# nrf54l15_application register map
Vendor: Nordic Semiconductor; Series: nrf54l; File version: 1
CPU: CM33 r0p4, little endian, MPU, FPU, 3 interrupt priority bits, 270 interrupts, 4 SAU regions
Registers are 32-bit, read-write, reset 0x0 unless marked. A register's access mark holds for its fields unless they carry their own. Offsets are from the block's base; [hi:lo] are bit positions; lines under a group give offsets from that group; {n}, {i} and the like mark numbered series; 'fields as' and 'values as' point back to an identical list.

## GLOBAL_SAADC_NS — Analog to Digital Converter 0
Base 0x400D5000
Same registers: GLOBAL_SAADC_S 0x500D5000
0x00 TASKS_START wo — Start the ADC and prepare the result buffer in RAM
  [0] TASKS_START
    1=Trigger task
0x04 TASKS_SAMPLE wo — Take one ADC sample, if scan is enabled all channels are sampled. This task requires that SAADC has started, i.e. EVENTS_STARTED was set and EVENTS_STOPPED was not.
  [0] TASKS_SAMPLE
    1=Trigger task
0x08 TASKS_STOP wo — Stop the ADC and terminate any on-going conversion
  [0] TASKS_STOP
    1=Trigger task
0x0C TASKS_CALIBRATEOFFSET wo — Starts offset auto-calibration Noise shaping should be disabled
  [0] TASKS_CALIBRATEOFFSET
    1=Trigger task
0x10 TASKS_CALIBRATELINEARITY wo — Starts linearity auto-calibration. TESTCTRL field LIN_CAL_ENABLE must be low. Noise shaping must be disabled.
  [0] TASKS_CALIBRATELINEARITY
    1=Trigger task
0x14 TASKS_CALIBRATEGAIN wo — Starts gain auto-calibration
  [0] TASKS_CALIBRATEGAIN
    1=Trigger task
0x18 TASKS_STOPDMA wo — Stops DMA transfer sub module
  [0] TASKS_STOPDMA
    1=Trigger task
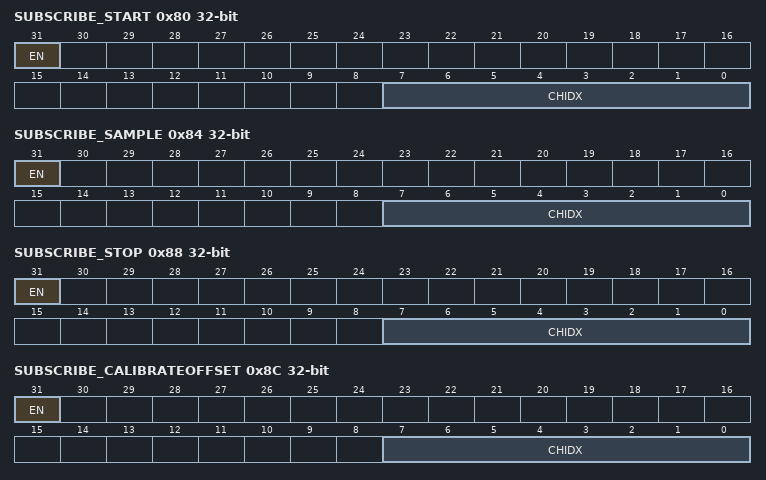
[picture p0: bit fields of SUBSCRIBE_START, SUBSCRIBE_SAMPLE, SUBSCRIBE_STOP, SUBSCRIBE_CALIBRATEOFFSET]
0x80 SUBSCRIBE_START — Subscribe configuration for task START
  [31] EN
    0=Disabled (Disable subscription); 1=Enabled (Enable subscription)
  [7:0] CHIDX — DPPI channel that task START will subscribe to
0x84 SUBSCRIBE_SAMPLE — Subscribe configuration for task SAMPLE
  [31] EN
    values as SUBSCRIBE_START.EN
  [7:0] CHIDX — DPPI channel that task SAMPLE will subscribe to
0x88 SUBSCRIBE_STOP — Subscribe configuration for task STOP
  [31] EN
    values as SUBSCRIBE_START.EN
  [7:0] CHIDX — DPPI channel that task STOP will subscribe to
0x8C SUBSCRIBE_CALIBRATEOFFSET — Subscribe configuration for task CALIBRATEOFFSET
  [31] EN
    values as SUBSCRIBE_START.EN
  [7:0] CHIDX — DPPI channel that task CALIBRATEOFFSET will subscribe to
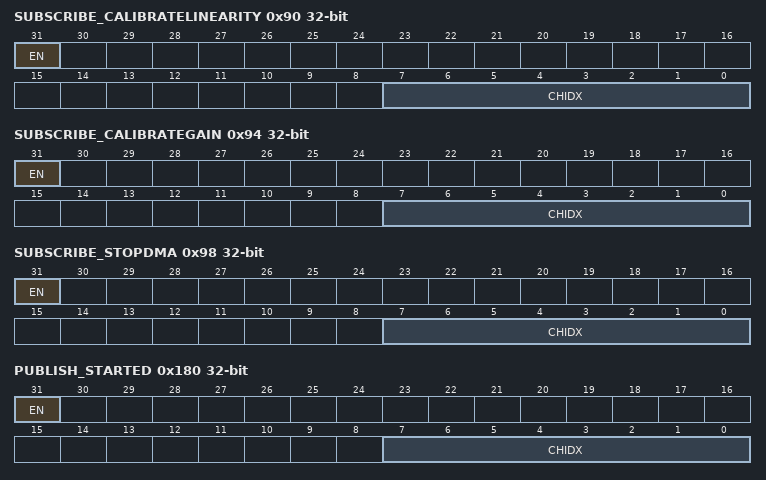
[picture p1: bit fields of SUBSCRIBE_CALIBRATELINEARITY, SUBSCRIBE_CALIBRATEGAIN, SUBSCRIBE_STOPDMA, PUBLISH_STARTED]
0x90 SUBSCRIBE_CALIBRATELINEARITY — Subscribe configuration for task CALIBRATELINEARITY
  [31] EN
    values as SUBSCRIBE_START.EN
  [7:0] CHIDX — DPPI channel that task CALIBRATELINEARITY will subscribe to
0x94 SUBSCRIBE_CALIBRATEGAIN — Subscribe configuration for task CALIBRATEGAIN
  [31] EN
    values as SUBSCRIBE_START.EN
  [7:0] CHIDX — DPPI channel that task CALIBRATEGAIN will subscribe to
0x98 SUBSCRIBE_STOPDMA — Subscribe configuration for task STOPDMA
  [31] EN
    values as SUBSCRIBE_START.EN
  [7:0] CHIDX — DPPI channel that task STOPDMA will subscribe to
0x100 EVENTS_STARTED — The ADC DMA has started
  [0] EVENTS_STARTED
    0=NotGenerated (Event not generated); 1=Generated (Event generated)
0x104 EVENTS_END — The ADC has filled up the Result buffer
  [0] EVENTS_END
    values as EVENTS_STARTED.EVENTS_STARTED
0x108 EVENTS_DONE — A conversion task has been completed. Depending on the mode, multiple conversions might be needed for a result to be transferred to RAM.
  [0] EVENTS_DONE
    values as EVENTS_STARTED.EVENTS_STARTED
0x10C EVENTS_RESULTDONE — A result is ready to get transferred to RAM. Result is available in REGRESULT register
  [0] EVENTS_RESULTDONE
    values as EVENTS_STARTED.EVENTS_STARTED
0x110 EVENTS_CALIBRATEDONE — Calibration is complete
  [0] EVENTS_CALIBRATEDONE
    values as EVENTS_STARTED.EVENTS_STARTED
0x114 EVENTS_STOPPED — The ADC DMA has stopped
  [0] EVENTS_STOPPED
    values as EVENTS_STARTED.EVENTS_STARTED
{0x118+8i} EVENTS_CH[{i}] (i=0..7) group — Peripheral events.
  0x00 LIMITH — Description cluster: Last results is above CH[n].LIMIT.HIGH
    [0] LIMITH — Last results is above CH[n].LIMIT.HIGH
      values as EVENTS_STARTED.EVENTS_STARTED
  0x04 LIMITL — Description cluster: Last results is below CH[n].LIMIT.LOW
    [0] LIMITL — Last results is below CH[n].LIMIT.LOW
      values as EVENTS_STARTED.EVENTS_STARTED
0x158 EVENTS_AHBERROR — EasyDMA encountered AHB error.
  [0] EVENTS_AHBERROR
    values as EVENTS_STARTED.EVENTS_STARTED
0x180 PUBLISH_STARTED — Publish configuration for event STARTED
  [31] EN
    0=Disabled (Disable publishing); 1=Enabled (Enable publishing)
  [7:0] CHIDX — DPPI channel that event STARTED will publish to
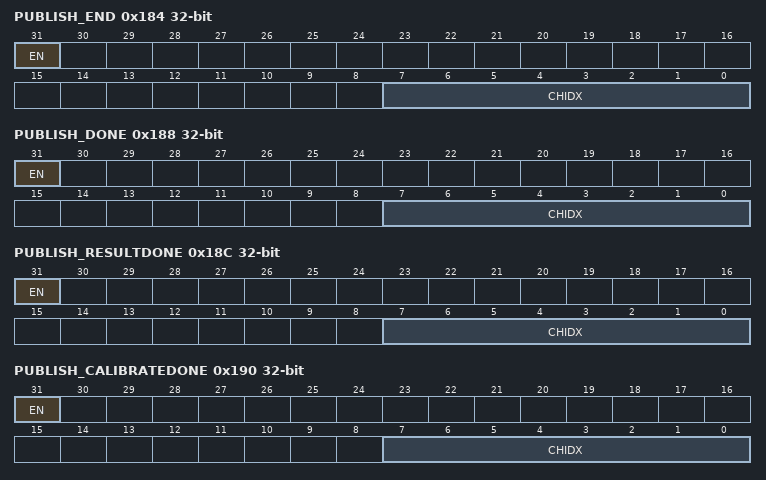
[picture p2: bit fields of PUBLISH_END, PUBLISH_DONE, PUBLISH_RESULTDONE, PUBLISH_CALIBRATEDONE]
0x184 PUBLISH_END — Publish configuration for event END
  [31] EN
    values as PUBLISH_STARTED.EN
  [7:0] CHIDX — DPPI channel that event END will publish to
0x188 PUBLISH_DONE — Publish configuration for event DONE
  [31] EN
    values as PUBLISH_STARTED.EN
  [7:0] CHIDX — DPPI channel that event DONE will publish to
0x18C PUBLISH_RESULTDONE — Publish configuration for event RESULTDONE
  [31] EN
    values as PUBLISH_STARTED.EN
  [7:0] CHIDX — DPPI channel that event RESULTDONE will publish to
0x190 PUBLISH_CALIBRATEDONE — Publish configuration for event CALIBRATEDONE
  [31] EN
    values as PUBLISH_STARTED.EN
  [7:0] CHIDX — DPPI channel that event CALIBRATEDONE will publish to
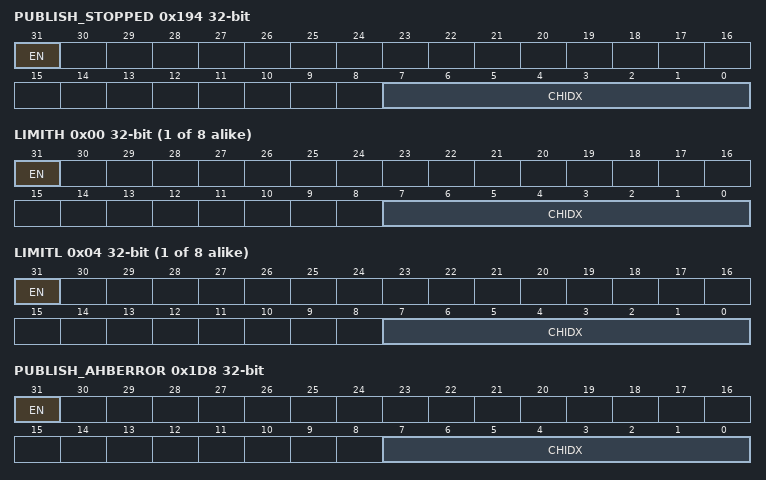
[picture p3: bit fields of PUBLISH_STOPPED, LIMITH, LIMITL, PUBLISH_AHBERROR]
0x194 PUBLISH_STOPPED — Publish configuration for event STOPPED
  [31] EN
    values as PUBLISH_STARTED.EN
  [7:0] CHIDX — DPPI channel that event STOPPED will publish to
{0x198+8i} PUBLISH_CH[{i}] (i=0..7) group — Publish configuration for events
  0x00 LIMITH — Description cluster: Publish configuration for event CH[n].LIMITH
    [31] EN
      values as PUBLISH_STARTED.EN
    [7:0] CHIDX — DPPI channel that event CH[n].LIMITH will publish to
  0x04 LIMITL — Description cluster: Publish configuration for event CH[n].LIMITL
    [31] EN
      values as PUBLISH_STARTED.EN
    [7:0] CHIDX — DPPI channel that event CH[n].LIMITL will publish to
0x1D8 PUBLISH_AHBERROR — Publish configuration for event AHBERROR
  [31] EN
    values as PUBLISH_STARTED.EN
  [7:0] CHIDX — DPPI channel that event AHBERROR will publish to
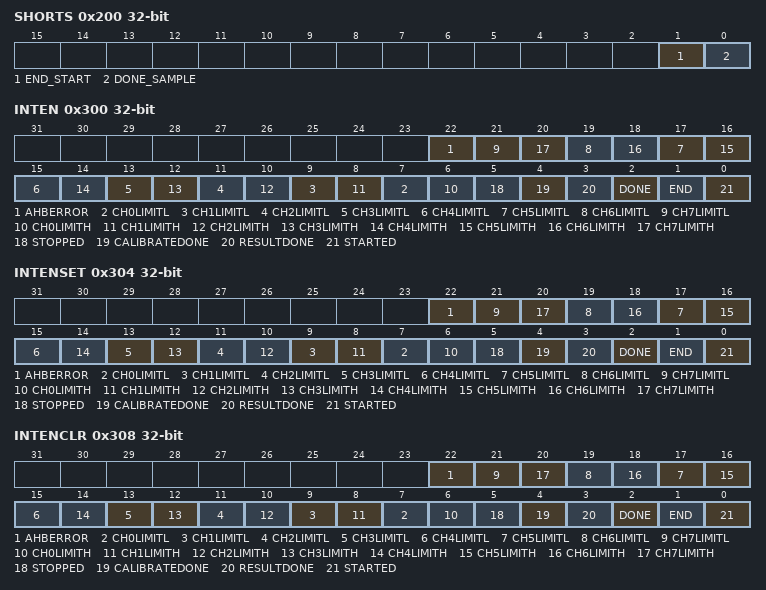
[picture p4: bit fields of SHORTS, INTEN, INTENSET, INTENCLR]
0x200 SHORTS — Shortcuts between local events and tasks
  [1] END_START — Shortcut between event END and task START
    0=Disabled (Disable shortcut); 1=Enabled (Enable shortcut)
  [0] DONE_SAMPLE — Shortcut between event DONE and task SAMPLE
    0=Disabled (Disable shortcut); 1=Enabled (Enable shortcut)
0x300 INTEN — Enable or disable interrupt
  [all] fields
    0=Disabled; 1=Enabled
  [22] AHBERROR — Enable or disable interrupt for event AHBERROR
  [2n+7] CH{n}LIMITL (n=0..7) — Enable or disable interrupt for event CH{n}LIMITL
  [2n+6] CH{n}LIMITH (n=0..7) — Enable or disable interrupt for event CH{n}LIMITH
  [5] STOPPED — Enable or disable interrupt for event STOPPED
  [4] CALIBRATEDONE — Enable or disable interrupt for event CALIBRATEDONE
  [3] RESULTDONE — Enable or disable interrupt for event RESULTDONE
  [2] DONE — Enable or disable interrupt for event DONE
  [1] END — Enable or disable interrupt for event END
  [0] STARTED — Enable or disable interrupt for event STARTED
0x304 INTENSET — Enable interrupt
  [all] fields
    on read: 0=Disabled (Read: Disabled); 1=Enabled (Read: Enabled) | on write: 1=Set (Enable)
  [22] AHBERROR — Write '1' to enable interrupt for event AHBERROR
  [2n+7] CH{n}LIMITL (n=0..7) — Write '1' to enable interrupt for event CH{n}LIMITL
  [2n+6] CH{n}LIMITH (n=0..7) — Write '1' to enable interrupt for event CH{n}LIMITH
  [5] STOPPED — Write '1' to enable interrupt for event STOPPED
  [4] CALIBRATEDONE — Write '1' to enable interrupt for event CALIBRATEDONE
  [3] RESULTDONE — Write '1' to enable interrupt for event RESULTDONE
  [2] DONE — Write '1' to enable interrupt for event DONE
  [1] END — Write '1' to enable interrupt for event END
  [0] STARTED — Write '1' to enable interrupt for event STARTED
0x308 INTENCLR — Disable interrupt
  [all] fields
    on read: 0=Disabled (Read: Disabled); 1=Enabled (Read: Enabled) | on write: 1=Clear (Disable)
  [22] AHBERROR — Write '1' to disable interrupt for event AHBERROR
  [2n+7] CH{n}LIMITL (n=0..7) — Write '1' to disable interrupt for event CH{n}LIMITL
  [2n+6] CH{n}LIMITH (n=0..7) — Write '1' to disable interrupt for event CH{n}LIMITH
  [5] STOPPED — Write '1' to disable interrupt for event STOPPED
  [4] CALIBRATEDONE — Write '1' to disable interrupt for event CALIBRATEDONE
  [3] RESULTDONE — Write '1' to disable interrupt for event RESULTDONE
  [2] DONE — Write '1' to disable interrupt for event DONE
  [1] END — Write '1' to disable interrupt for event END
  [0] STARTED — Write '1' to disable interrupt for event STARTED
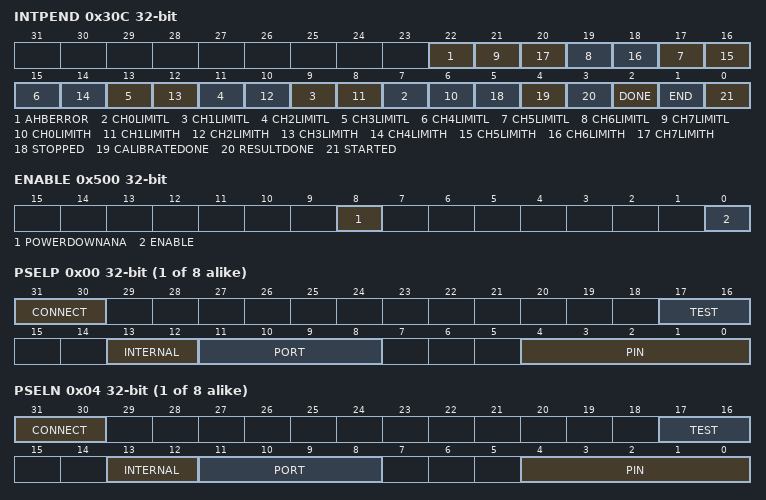
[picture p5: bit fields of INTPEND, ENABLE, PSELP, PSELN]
0x30C INTPEND ro — Pending interrupts
  [all] fields
    on read: 0=NotPending (Read: Not pending); 1=Pending (Read: Pending)
  [22] AHBERROR — Read pending status of interrupt for event AHBERROR
  [2n+7] CH{n}LIMITL (n=0..7) — Read pending status of interrupt for event CH{n}LIMITL
  [2n+6] CH{n}LIMITH (n=0..7) — Read pending status of interrupt for event CH{n}LIMITH
  [5] STOPPED — Read pending status of interrupt for event STOPPED
  [4] CALIBRATEDONE — Read pending status of interrupt for event CALIBRATEDONE
  [3] RESULTDONE — Read pending status of interrupt for event RESULTDONE
  [2] DONE — Read pending status of interrupt for event DONE
  [1] END — Read pending status of interrupt for event END
  [0] STARTED — Read pending status of interrupt for event STARTED
0x400 STATUS ro
  [0] STATUS
    0=Ready (ADC is ready. No on-going conversion.); 1=Busy (ADC is busy. Conversion is in progress.)
0x404 PCRMSTATUS ro
  [0] ACK — PCRM Ack Status for the PCRM clean power request
    0=NoAck (Ack not received.); 1=Ack (Ack received.)
0x408 STATUSANA ro — Status bit for analog macro
  [0] POWERED
    1=Powered (Analog macro is fully powered on); 0=Unpowered (Analog macro is not fully powered on)
0x440 TRIM group — Unspecified
  {0x0+4j} LINCALCOEFF[{j}] (j=0..5) — Description collection: Linearity calibration coefficient
    [15:0] VAL — value
0x500 ENABLE — Enable or disable ADC
  [8] POWERDOWNANA — Power down analog between samples.
    0=KeepOn (Keep analog on between samples); 1=PowerDown (Turn off analog between samples)
  [0] ENABLE — Enable or disable ADC
    0=Disabled (Disable ADC); 1=Enabled (Enable ADC)
{0x510+0x10*i} CH[{i}] (i=0..7) group — Unspecified
  0x00 PSELP — Description cluster: Input positive pin selection for CH[n]
    [31:30] CONNECT — Connection
      0=NC (Not connected); 1=AnalogInput (Select analog input); 2=Internal (Selects internal inputs.); 3=Test (Selects test inputs.)
    [17:16] TEST — Test input selection for Analog positive input when CH[n].PSELP.CONNECT = Test
      0=ATB2; 1=ATB1; 2=AVSS; 3=SELREF (Selected reference, voltage determined by PADC_REFSEL)
    [13:12] INTERNAL — Internal input selection for analog positive input when CH[n].PSELP.CONNECT = Internal
      0=Avdd (Connected to the internal 0.9V analog supply rail); 1=Dvdd (Connected to the internal 0.9V digital supply rail); 2=Vdd (Connected to VDD); 3=Reserved for future use
    [11:8] PORT — GPIO port selection
    [4:0] PIN — GPIO pin selection.
  0x04 PSELN — Description cluster: Input negative pin selection for CH[n]
    [31:30] CONNECT — Connection
      values as CH[0].PSELP.CONNECT
    [17:16] TEST — Test input selection for Analog negative input when CH[n].PSELN.CONNECT = Test
      0=ATB0; 1=ATB1; 2=AVSS; 3=SELREF (Selected reference, voltage determined by PADC_REFSEL)
    [13:12] INTERNAL — Internal input selection for Analog negative input when CH[n].PSELN.CONNECT = Internal
      0=Connected to VDD_ANA_0V9; 1=Connected to VDD_DIG_0V9; 2=Connected to VDD_AO_3V0; 3=Reserved for future use
    [11:8] PORT — GPIO Port selection
    [4:0] PIN — GPIO pin selection.
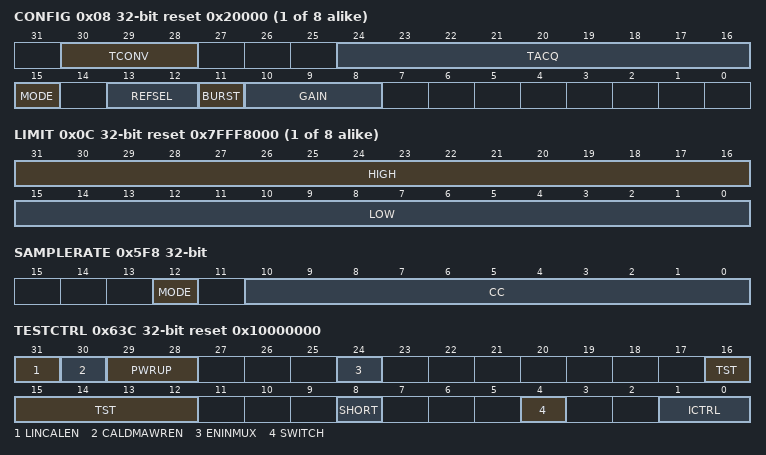
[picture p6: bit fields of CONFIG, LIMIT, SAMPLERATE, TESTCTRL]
  0x08 CONFIG reset 0x20000 — Description cluster: Input configuration for CH[n]
    [30:28] TCONV — Conversion time. Resulting conversion time is ((TCONV+1) x 250 ns)
    [24:16] TACQ — Acquisition time, the time the ADC uses to sample the input voltage. Resulting acquistion time is ((TACQ+1) x 125 ns)
    [15] MODE — Enable differential mode
      0=SE (Single ended, PSELN will be ignored, negative input to ADC shorted to GND); 1=Differential
    [13:12] REFSEL — Reference control
      0=Internal reference (0.9 V); 1=External reference given at PADC_EXT_REF_1V2
    [11] BURST — Enable burst mode
      0=Disabled (Burst mode is disabled (normal operation)); 1=Enabled (Burst mode is enabled. SAADC takes 2^OVERSAMPLE number of samples as fast as it can, and sends the average to Data RAM.)
    [10:8] GAIN — Gain control
      0=2; 1=1; {v}=Gain2_{v+1} (2/{v+1}) (v=2..7)
  0x0C LIMIT reset 0x7FFF8000 — Description cluster: High/low limits for event monitoring a channel
    [31:16] HIGH — High level limit
    [15:0] LOW — Low level limit
0x5EC REGRESULT ro — Last conversion result
  [31:0] REGRESULT — Result of the previous ADC conversion, as written to RAM
0x5F0 RESOLUTION reset 0x1 — Resolution configuration
  [2:0] VAL — Set the resolution
    0=8bit; 1=10bit; 2=12bit; 3=14bit; 4=16bit
0x5F4 OVERSAMPLE — Oversampling configuration. OVERSAMPLE should not be combined with SCAN unless burst is enabled. The RESOLUTION is applied before averaging, thus for high OVERSAMPLE a higher RESOLUTION should be used.
  [3:0] OVERSAMPLE — Oversample control
    0=Bypass oversampling; 1=Over2x (Oversample 2x); 2=Over4x (Oversample 4x); 3=Over8x (Oversample 8x); 4=Over16x (Oversample 16x); 5=Over32x (Oversample 32x); 6=Over64x (Oversample 64x); 7=Over128x (Oversample 128x); 8=Over256x (Oversample 256x); 9=Over512x (Oversample 512x); 10=Over1024x (Oversample 1024x); 11=Over2048x (Oversample 2048x); 12=Over4096x (Oversample 4096x)
0x5F8 SAMPLERATE — Configures the sampling rate for either task-triggered or continuous operation using a local timer
  [12] MODE — Select mode for sample rate control
    0=Task (Rate is controlled from SAMPLE task); 1=Timers (Rate is controlled from local timer (use CC to control the rate))
  [10:0] CC — Capture and compare value. Sample rate is 16 MHz/CC
0x5FC PCRMREQ — PCRM request for clean power
  [0] REQ — Request
    0=Disabled (Request disabled.); 1=Enabled (Request enabled.)
0x628 RESULT group — RESULT EasyDMA channel
  0x00 DMAENABLE — This register has no other function than defining the value on the dmaChannelPeripheralEnable output. (which is not connected)
    [0] ENABLE — Enable DMA
  0x04 PTR — Data pointer
  0x08 MAXCNT — Maximum number of buffer bytes to transfer. Note that one sample is two bytes.
    [14:0] MAXCNT
  0x0C AMOUNT ro — Number of buffer bytes transferred since last START, updated after the END or STOPPED events
    [14:0] AMOUNT — Number of buffer bytes transferred since last START, updated after the END or STOPPED events.
  0x10 CURRENTAMOUNT ro — Number of buffer bytes transferred since last START, continuously updated
    [14:0] AMOUNT — Number of buffer bytes transferred since last START, continuously updated.
0x63C TESTCTRL reset 0x10000000 — Control signals used during test of ADC
  [31] LINCALEN — Enables the use of linear calibration values TRIM.LINCALCOEFF[n]
    0=Disabled (Use of linear calibration is disabled); 1=Enabled (Use of linear calibration is enabled)
  [30] CALDMAWREN — Enable writing calibration values to DMA
    0=Disabled (Writing values is disabled); 1=Enabled (Writing values is enabled)
  [29:28] PWRUP — Power-up time
    0=6us; 1=10us; 2=15us; 3=20us
  [24] ENINMUX — Will enable the input mux in the ADC. See design description for coding.
  [16:12] TST — Test bus for ADC core. See design description for coding
  [8] SHORT — Short input. Used to measure offset of ADC. See design description for coding
  [4] SWITCH — Swap positive and negative input. See design description for coding
  [1:0] ICTRL — Multiply the current level of the internal bias current IBPSR_10U
    2=I20uA (20 uA); 3=I15uA (15 uA); 0=I10uA (10 uA (default)); 1=I5uA (5 uA)
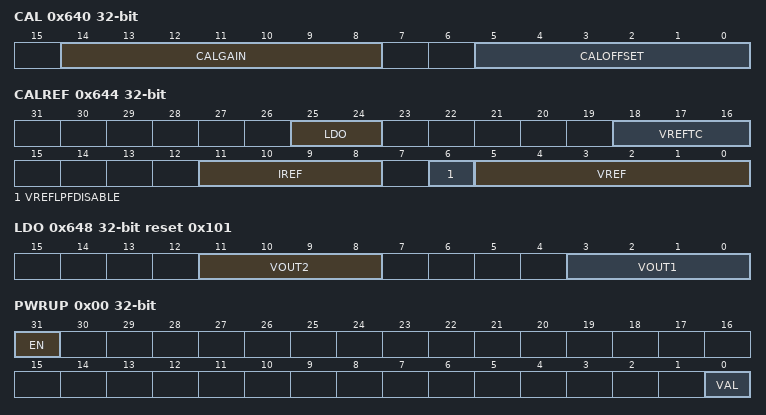
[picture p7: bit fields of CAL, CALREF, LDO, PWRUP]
0x640 CAL — Calibration control for offset and gain error
  [14:8] CALGAIN — Offset binary coding
    0=Default gain, for +1/2 input (assume full-scale = +-1) the output will be 1024; 63=High gain setting; 64=Low (Low gain setting)
  [5:0] CALOFFSET — Calibration control for offset error. Sign-magnitude coding
    0=Default setting; 31=MaxPos (Maximum positive offset); 32=MaxNeg (maximum negative offset)
0x644 CALREF — Calibration control for reference voltage
  [25:24] LDO — Calibration code for LDO VREF. See design description for coding
  [18:16] VREFTC — Calibration code for reference temperature coefficient. See design description for coding
  [11:8] IREF — Calibration control for reference current. IREF is 2s complement, 4.45 percent step size
    7=Max (Maximum current (+31.3 percent ish)); 0=Default current (10uA); 8=Min (Minimum current (-35.6 percent ish))
  [6] VREFLPFDISABLE — Disable the internal reference low pass filter
  [5:0] VREF — Offset binary coding
    0=Default vref, in typical corner VREF=0.9V; 63=High (Low output code (high reference voltage)); 0=Low (High output code (low reference voltage))
0x648 LDO reset 0x101 — Internal LDO output voltage control
  [11:8] VOUT2 — Secontary LDO output voltage control. See design description for coding
  [3:0] VOUT1 — Primary LDO output voltage control. See design description for coding
0x654 NOISESHAPE — SAADC provides two operational noise shaping modes (one that prioritizes higher bandwith, while the other prioritizes higher accuracy) that allow trade-offs between ADC resolution, power consumption, and signal bandwidth.
  [1:0] NOISESHAPE — Noise shaping configuration
    0=Disable noiseshaping. Configurable oversampling.; 1=NS1 (Noiseshaping and decimating. Larger passband. Decimation ratio 8, 125 kS/s, with resulting bandwidth around 45 kHz. Takes precedence over the OVERSAMPLING register.); 2=NS2 (Noiseshaping and decimating. Smaller passband. Decimation ratio 32, 31.25 kS/s, with resulting bandwidth around 7 kHz. Takes precedence over the OVERSAMPLING register.); 3=Stage1 (Moonlight/Lilium: Result from common 1st stage filter. For debugging only. Configurable oversampling, but this mode without oversampling is not meaningful (noise shaping one sample)); 1=Audio (Deprecated enumerator - Use enumerator NS1 for future compatibility.); 2=Accuracy (Deprecated enumerator - Use enumerator NS2 for future compatibility.)
0x658 EASYDMAMODE reset 0x1 — Configure EasyDMA mode.
  [0] LPOP — Enable low-power operation, or use low-latency
    0=Low-latency operation; 1=Low-power operation
0x660 TERMINATEONAHBERROR — Enable EasyDMA termination on AHB error
  [0] ENABLE — Enable termination on AHB error
    0=Disabled (Termination on AHB error disabled); 1=Enabled (Termination on AHB error enabled)
0x664 AHBERRORADDRESS ro — Address of the last AHB error transaction
  [31:0] ADDRESS
0x700 OVERRIDE group — Unspecified
  0x00 PWRUP — Override the PWRUP signal to the analog module
    [31] EN — Enable the override
      0=Disabled (Override is disabled); 1=Enabled (Override is enabled)
    [0] VAL — Override value for the signal
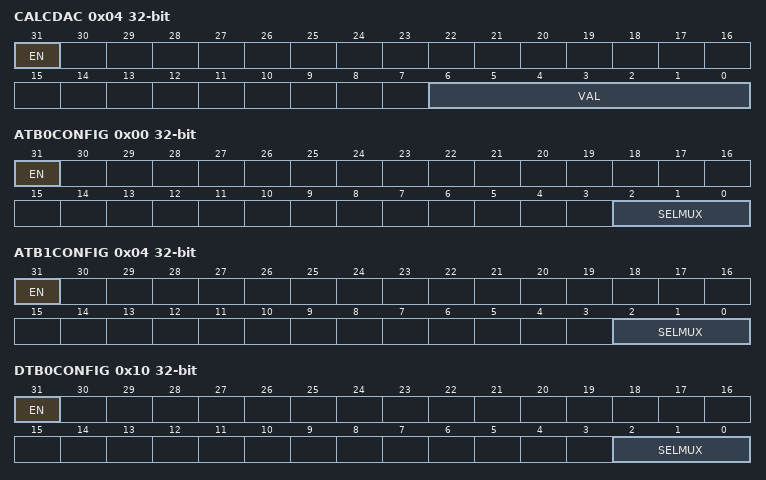
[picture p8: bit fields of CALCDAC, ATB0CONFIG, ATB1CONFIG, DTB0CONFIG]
  0x04 CALCDAC — Override the CAL_CDAC signal to the analog module
    [31] EN — Enable the override
      values as OVERRIDE.PWRUP.EN
    [6:0] VAL — Override value for the signal
0x800 DFT group — Unspecified
  0x00 ATB0CONFIG — Analog Test Bus 0 (ATB0) configuration
    [31] EN — Enable the analog test bus
      0=Disabled (Analog test bus is disabled); 1=Enabled (Analog test bus is enabled)
    [2:0] SELMUX — Select multiplexer for ATB0
      0=InMux (ATB0 connected to PADC_INMUX, available on PADC_IN); 1=Vref (ATB0 connected to VREF); 2=VrefBuff (ATB0 connected to VREF_BUFF); 3=VrefIbpsr10U (ATB0 connected to ATB_PADC_VREF_IBPSR_10U for current measurement); 4=VrefIbps3U (ATB0 connected to ATB_PADC_VREF_IBPS_3U); 5=VrefLpfDisabled (ATB0 connected to VREF, internal reference with LPF bypassed.); 6=Spare1 (Spare pin); 7=Spare2 (Spare pin)
  0x04 ATB1CONFIG — Analog Test Bus 1 (ATB1) configuration
    [31] EN — Enable the analog test bus
      values as DFT.ATB0CONFIG.EN
    [2:0] SELMUX — Select multiplexer for ATB1
      0=Inmux (ATB1 connected to PADC_INMUX, available on both PADC_IP and PADC_IN); 1=VrefViaAtbuf (ATB1 connected to VREF via ATBBUF); 2=VrefBuffViaAtbuf (ATB1 connected to VREF_BUFF via ATBUF); 3=Ldo (ATB1 connected to PADC_LDO to measure 1.5V via ATBUF); 4=Spare0 (Unspecified); 5=VrefLdo (ATB1 connected to VREF_LDO to measure 1.5V via ATBUF); 6=Spare1 (Spare pin); 7=Spare2 (Spare pin)
  0x08 ATB2CONFIG — Analog Test Bus 2 (ATB2) configuration
    [31] EN — Enable the analog test bus
      0=Disabled (Analog test bus is disabled); 1=Enabled (Analog test bus is enabled and connected to PADC_INMUX available on PADC_IP)
  0x10 DTB0CONFIG — Digital Test Bus 0 (DTB0) configuration
    [31] EN — Enable the digital test bus
      0=Disabled (Digital test bus is disabled); 1=Enabled (Digital test bus is enabled)
    [2:0] SELMUX — Select multiplexer for DTB0
      0=READY (READY_PADC_AO_0V8); 1=READYVREF (READY_PADC_VREF_AO_0V8); 2=SETTLED (SETTLED_VDD_INT_AO_0V8); 3=INTCONVERT (INT_CONVERT_0V8); 4=INTDONE (INT_DONE_0V8); 5=INTAMPLFIY (INT_AMPLFIY_0V8); 6=Spare0 (Spare pin); 7=Spare1 (Spare pin)
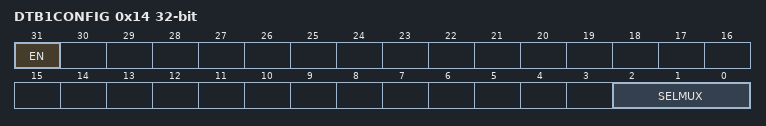
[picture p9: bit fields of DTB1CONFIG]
  0x14 DTB1CONFIG — Digital Test Bus 1 (DTB1) configuration
    [31] EN — Enable the digital test bus
      values as DFT.DTB0CONFIG.EN
    [2:0] SELMUX — Select multiplexer for DTB1
      0=INTIDLE (INT_IDLE_0V8); 1=INTSAMPLE (INT_SAMPLE_0V8); 2=INTAMPLFIY (INT_AMPLFIY_0V8); 3=INTCONVERT (INT_CONVERT_0V8); 4=INTDONE (INT_DONE_0V8); 5=ENNSERRFEEDBACK (EN_NS_ERR_FEEDBACK_0V8); 6=Spare0 (Spare pin); 7=Spare1 (Spare pin)

## Notices in the file
Copyright (c) 2010 - 2025, Nordic Semiconductor ASA
All rights reserved.
Redistribution and use in source and binary forms, with or without modification,
are permitted provided that the following conditions are met:
1. Redistributions of source code must retain the above copyright notice, this
list of conditions and the following disclaimer.
2. Redistributions in binary form, except as embedded into a Nordic
Semiconductor ASA integrated circuit in a product or a software update for
such product, must reproduce the above copyright notice, this list of
conditions and the following disclaimer in the documentation and/or other
materials provided with the distribution.
3. Neither the name of Nordic Semiconductor ASA nor the names of its
contributors may be used to endorse or promote products derived from this
software without specific prior written permission.
4. This software, with or without modification, must only be used with a
Nordic Semiconductor ASA integrated circuit.
5. Any software provided in binary form under this license must not be reverse
engineered, decompiled, modified and/or disassembled.
THIS SOFTWARE IS PROVIDED BY NORDIC SEMICONDUCTOR ASA "AS IS" AND ANY EXPRESS
OR IMPLIED WARRANTIES, INCLUDING, BUT NOT LIMITED TO, THE IMPLIED WARRANTIES
OF MERCHANTABILITY, NONINFRINGEMENT, AND FITNESS FOR A PARTICULAR PURPOSE ARE
DISCLAIMED. IN NO EVENT SHALL NORDIC SEMICONDUCTOR ASA OR CONTRIBUTORS BE
LIABLE FOR ANY DIRECT, INDIRECT, INCIDENTAL, SPECIAL, EXEMPLARY, OR
CONSEQUENTIAL DAMAGES (INCLUDING, BUT NOT LIMITED TO, PROCUREMENT OF SUBSTITUTE
GOODS OR SERVICES; LOSS OF USE, DATA, OR PROFITS; OR BUSINESS INTERRUPTION)
HOWEVER CAUSED AND ON ANY THEORY OF LIABILITY, WHETHER IN CONTRACT, STRICT
LIABILITY, OR TORT (INCLUDING NEGLIGENCE OR OTHERWISE) ARISING IN ANY WAY OUT
OF THE USE OF THIS SOFTWARE, EVEN IF ADVISED OF THE POSSIBILITY OF SUCH DAMAGE.
